AUTOSAR XML (schema 4-3-0)
package /ComponentTypes
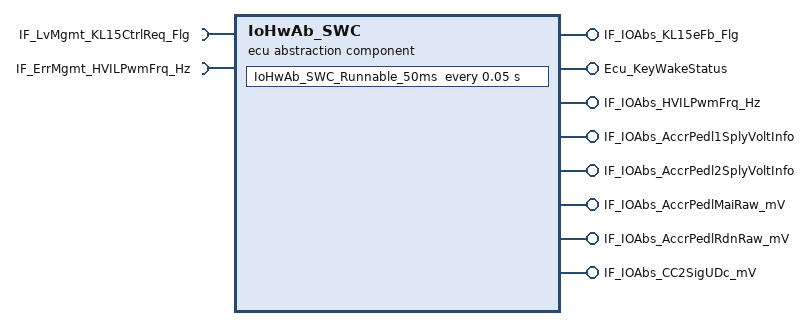
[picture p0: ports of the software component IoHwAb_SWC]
  ecu abstraction sw component type IoHwAb_SWC
    require port IF_LvMgmt_KL15CtrlReq_Flg: nonqueued-receiver-com-spec=data-element=tec_LvMgmt_KL15CtrlReq_Flg, required-interface=IF_LvMgmt_KL15CtrlReq_Flg
    provide port IF_IOAbs_KL15eFb_Flg: nonqueued-sender-com-spec=tec_IOAbs_KL15eFb_Flg, provided-interface=IF_IOAbs_KL15eFb_Flg
    provide port Ecu_KeyWakeStatus: nonqueued-sender-com-spec=Keywake, provided-interface=Ecu_KeyWakeStatus
    provide port IF_IOAbs_HVILPwmFrq_Hz: nonqueued-sender-com-spec=tec_IOAbs_HVILPwmFrq_Hz, provided-interface=IF_IOAbs_HVILPwmFrq_Hz
    require port IF_ErrMgmt_HVILPwmFrq_Hz: nonqueued-receiver-com-spec=data-element=tec_ErrMgmt_HVILPwmFrq_Hz, required-interface=IF_ErrMgmt_HVILPwmFrq_Hz
    5 x provide port:
      IF_IOAbs_AccrPedl1SplyVoltInfo: nonqueued-sender-com-spec=tec_IOAbs_AccrPedl1SplyVoltInfo, provided-interface=IF_IOAbs_AccrPedl1SplyVoltInfo
      IF_IOAbs_AccrPedl2SplyVoltInfo: nonqueued-sender-com-spec=tec_IOAbs_AccrPedl2SplyVoltInfo, provided-interface=IF_IOAbs_AccrPedl2SplyVoltInfo
      IF_IOAbs_AccrPedlMaiRaw_mV: nonqueued-sender-com-spec=tec_IOAbs_AccrPedlMaiRaw_mV, provided-interface=IF_IOAbs_AccrPedlMaiRaw_mV
      IF_IOAbs_AccrPedlRdnRaw_mV: nonqueued-sender-com-spec=tec_IOAbs_AccrPedlRdnRaw_mV, provided-interface=IF_IOAbs_AccrPedlRdnRaw_mV
      IF_IOAbs_CC2SigUDc_mV: nonqueued-sender-com-spec=tec_IOAbs_CC2SigUDc_mV, provided-interface=IF_IOAbs_CC2SigUDc_mV
    behavior IoHwAb_SWC_InternalBehavior
      timing event TMT_IoHwAb_SWC_Runnable_50ms: start-on-event=IoHwAb_SWC_Runnable_50ms, period=0.05
      runnable IoHwAb_SWC_Runnable_50ms
        data-receive-point-by-arguments:
          access REC_IF_LvMgmt_KL15CtrlReq_Flg_tec_LvMgmt_KL15CtrlReq_Flg: accessed-variable=IF_LvMgmt_KL15CtrlReq_Flg.tec_LvMgmt_KL15CtrlReq_Flg
          access REC_IF_ErrMgmt_HVILPwmFrq_Hz_tec_ErrMgmt_HVILPwmFrq_Hz: accessed-variable=IF_ErrMgmt_HVILPwmFrq_Hz.tec_ErrMgmt_HVILPwmFrq_Hz
        data-send-points:
          8 x access:
            SEND_IF_IOAbs_KL15eFb_Flg_tec_IOAbs_KL15eFb_Flg: accessed-variable=IF_IOAbs_KL15eFb_Flg.tec_IOAbs_KL15eFb_Flg
            SEND_Ecu_KeyWakeStatus_Keywake: accessed-variable=Ecu_KeyWakeStatus.Keywake
            SEND_IF_IOAbs_HVILPwmFrq_Hz_tec_IOAbs_HVILPwmFrq_Hz: accessed-variable=IF_IOAbs_HVILPwmFrq_Hz.tec_IOAbs_HVILPwmFrq_Hz
            SEND_IF_IOAbs_AccrPedl1SplyVoltInfo_tec_IOAbs_AccrPedl1SplyVoltInfo: accessed-variable=IF_IOAbs_AccrPedl1SplyVoltInfo.tec_IOAbs_AccrPedl1SplyVoltInfo
            SEND_IF_IOAbs_AccrPedl2SplyVoltInfo_tec_IOAbs_AccrPedl2SplyVoltInfo: accessed-variable=IF_IOAbs_AccrPedl2SplyVoltInfo.tec_IOAbs_AccrPedl2SplyVoltInfo
            SEND_IF_IOAbs_AccrPedlMaiRaw_mV_tec_IOAbs_AccrPedlMaiRaw_mV: accessed-variable=IF_IOAbs_AccrPedlMaiRaw_mV.tec_IOAbs_AccrPedlMaiRaw_mV
            SEND_IF_IOAbs_AccrPedlRdnRaw_mV_tec_IOAbs_AccrPedlRdnRaw_mV: accessed-variable=IF_IOAbs_AccrPedlRdnRaw_mV.tec_IOAbs_AccrPedlRdnRaw_mV
            SEND_IF_IOAbs_CC2SigUDc_mV_tec_IOAbs_CC2SigUDc_mV: accessed-variable=IF_IOAbs_CC2SigUDc_mV.tec_IOAbs_CC2SigUDc_mV
  swc implementation IoHwAb_SWC_Implementation: behavior=IoHwAb_SWC_InternalBehavior
